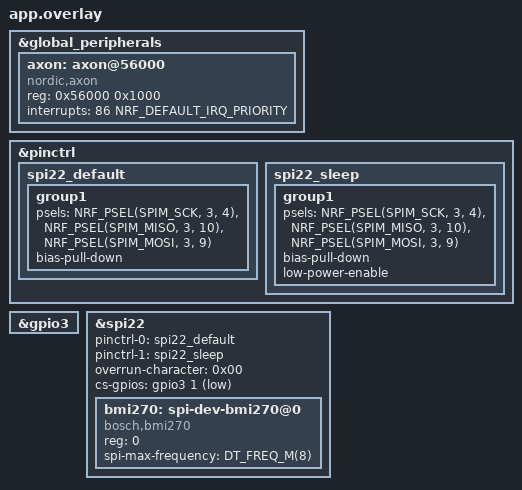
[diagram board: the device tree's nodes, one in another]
/*
 * Copyright (c) 2026 Nordic Semiconductor ASA
 *
 * SPDX-License-Identifier: LicenseRef-Nordic-5-Clause
 */

&global_peripherals {
	axon: axon@56000 {
		compatible = "nordic,axon";
		reg = <0x56000 0x1000>;
		interrupts = <86 NRF_DEFAULT_IRQ_PRIORITY>;
		status = "okay";
	};
};

&pinctrl {
	spi22_default: spi22_default {
		group1 {
			psels = <NRF_PSEL(SPIM_SCK, 3, 4)>,
				<NRF_PSEL(SPIM_MISO, 3, 10)>,
				<NRF_PSEL(SPIM_MOSI, 3, 9)>;
			bias-pull-down;
		};
	};

	spi22_sleep: spi22_sleep {
		group1 {
			psels = <NRF_PSEL(SPIM_SCK, 3, 4)>,
				<NRF_PSEL(SPIM_MISO, 3, 10)>,
				<NRF_PSEL(SPIM_MOSI, 3, 9)>;
			bias-pull-down;
			low-power-enable;
		};
	};
};

&gpio3 {
	status = "okay";
};

&spi22 {
	status = "okay";
	pinctrl-0 = <&spi22_default>;
	pinctrl-1 = <&spi22_sleep>;
	pinctrl-names = "default", "sleep";
	overrun-character = <0x00>;
	cs-gpios = <&gpio3 1 GPIO_ACTIVE_LOW>;

	bmi270: spi-dev-bmi270@0 {
		compatible = "bosch,bmi270";
		status = "okay";
		reg = <0>;
		spi-max-frequency = <DT_FREQ_M(8)>;
	};
};
